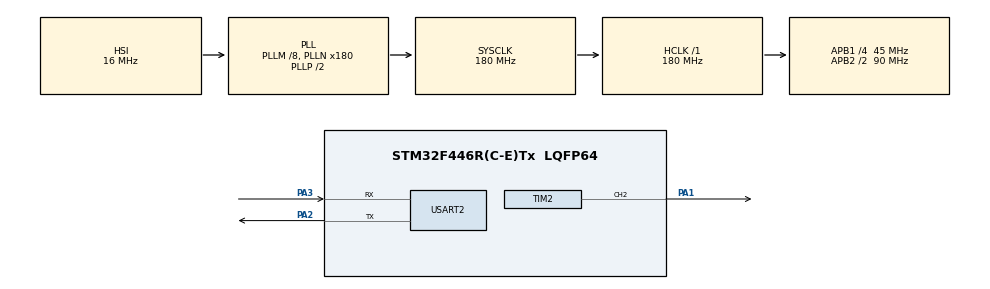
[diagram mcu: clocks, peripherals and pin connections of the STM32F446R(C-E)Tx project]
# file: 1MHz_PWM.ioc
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Mcu.Family=STM32F4
Mcu.Name=STM32F446R(C-E)Tx
Mcu.Package=LQFP64
NVIC.PriorityGroup=NVIC_PRIORITYGROUP_0
PA1.Signal=S_TIM2_CH2
PA13.Mode=Serial_Wire
PA13.Signal=SYS_JTMS-SWDIO
PA14.Mode=Serial_Wire
PA14.Signal=SYS_JTCK-SWCLK
PA2.Mode=Asynchronous
PA2.Signal=USART2_TX
PA3.Mode=Asynchronous
PA3.Signal=USART2_RX
PH0-OSC_IN.Mode=HSE-External-Oscillator
PH0-OSC_IN.Signal=RCC_OSC_IN
PH1-OSC_OUT.Mode=HSE-External-Oscillator
PH1-OSC_OUT.Signal=RCC_OSC_OUT
ProjectManager.HeapSize=0x200
ProjectManager.StackSize=0x400
ProjectManager.TargetToolchain=STM32CubeIDE
RCC.48MHZClocksFreq_Value=84000000
RCC.AHBFreq_Value=180000000
RCC.APB1CLKDivider=RCC_HCLK_DIV4
RCC.APB1Freq_Value=45000000
RCC.APB1TimFreq_Value=90000000
RCC.APB2CLKDivider=RCC_HCLK_DIV2
RCC.APB2Freq_Value=90000000
RCC.APB2TimFreq_Value=180000000
RCC.CortexFreq_Value=180000000
RCC.FLatency-AdvancedSettings=FLASH_LATENCY_5
RCC.HCLKFreq_Value=180000000
RCC.HSE_VALUE=8000000
RCC.HSI_VALUE=16000000
RCC.PLLM=8
RCC.PLLN=180
RCC.SYSCLKFreq_VALUE=180000000
RCC.SYSCLKSource=RCC_SYSCLKSOURCE_PLLCLK
RCC.USBFreq_Value=180000000
RCC.VCOOutputFreq_Value=360000000
SH.S_TIM2_CH2.0=TIM2_CH2,PWM Generation2 CH2
TIM2.Channel-PWM\ Generation2\ CH2=TIM_CHANNEL_2
TIM2.Period=179 
USART2.VirtualMode=VM_ASYNC
VP_TIM2_VS_ClockSourceINT.Mode=Internal
board=NUCLEO-F446RE

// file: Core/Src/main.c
/* USER CODE BEGIN Header */
/**
  ******************************************************************************
  * @file           : main.c
  * @brief          : Main program body
  ******************************************************************************
  * @attention
  *
  * Copyright (c) 2026 STMicroelectronics.
  * All rights reserved.
  *
  ******************************************************************************
  */
/* USER CODE END Header */

#include "main.h"
#include <stdlib.h>
//for an example

TIM_HandleTypeDef htim2;
UART_HandleTypeDef huart2;

/* USER CODE BEGIN PV */
uint8_t rx_char;
char rx_buffer[4];
uint32_t rx_index = 0;
uint8_t rx_overflow = 0;

char *endptr;
unsigned long requested_mhz;
/* USER CODE END PV */

void SystemClock_Config(void);
static void MX_GPIO_Init(void);
static void MX_TIM2_Init(void);
static void MX_USART2_UART_Init(void);

/* USER CODE BEGIN PFP */
void PWM_SetFrequency(uint32_t frequency_hz);
/* USER CODE END PFP */

int main(void)
{

  /* MCU Configuration--------------------------------------------------------*/

  HAL_Init();

  SystemClock_Config();

  MX_GPIO_Init();
  MX_TIM2_Init();
  MX_USART2_UART_Init();

  /* USER CODE BEGIN 2 */

  if (HAL_TIM_PWM_Start(&htim2, TIM_CHANNEL_2) != HAL_OK)
  {
    Error_Handler();
  }

  const char Values[] =
      "\r\nPWM controller ready\r\n"
      "Enter a frequency from 1 to 10 MHz, then press Enter.\r\n";

  HAL_UART_Transmit(&huart2, (uint8_t *)Values,
                    sizeof(Values) - 1U, HAL_MAX_DELAY);

  /* USER CODE END 2 */

  /* Infinite loop */
  while (1)
  {

    if (HAL_UART_Receive(&huart2, &rx_char, 1, HAL_MAX_DELAY) == HAL_OK)
    {
      if (rx_char == '\r')
      {
        /* Ignore carriage return */
      }
      else if (rx_char == '\n')
      {
        rx_buffer[rx_index] = '\0';

        if (rx_overflow == 0 && rx_index > 0U)
        {
          requested_mhz = strtoul(rx_buffer, &endptr, 10);

          if (endptr != rx_buffer &&
              *endptr == '\0' &&
              requested_mhz >= 1UL &&
              requested_mhz <= 10UL)
          {
            uint32_t requested_hz =
                (uint32_t)requested_mhz * 1000000U;

            PWM_SetFrequency(requested_hz);

            const char message[] = "PWM frequency updated\r\n";

            HAL_UART_Transmit(&huart2, (uint8_t *)message,sizeof(message) - 1U, HAL_MAX_DELAY);
          }
          else
          {
            const char message[] =
                "Invalid input. Enter 1 to 10 MHz.\r\n";

            HAL_UART_Transmit(&huart2, (uint8_t *)message,sizeof(message) - 1U, HAL_MAX_DELAY);
          }
        }
        else
        {
          const char message[] =
              "Invalid or empty input. Enter 1 to 10 MHz.\r\n";

          HAL_UART_Transmit(&huart2, (uint8_t *)message,sizeof(message) - 1U, HAL_MAX_DELAY);
        }

        rx_index = 0;
        rx_overflow = 0;
      }
      else
      {
        if (rx_index < sizeof(rx_buffer) - 1U)
        {
          rx_buffer[rx_index] = (char)rx_char;
          rx_index++;
        }
        else
        {
          rx_overflow = 1;
        }
      }
    }

  }
}

void SystemClock_Config(void)
{
  RCC_OscInitTypeDef RCC_OscInitStruct = {0};
  RCC_ClkInitTypeDef RCC_ClkInitStruct = {0};

  __HAL_RCC_PWR_CLK_ENABLE();
  __HAL_PWR_VOLTAGESCALING_CONFIG(PWR_REGULATOR_VOLTAGE_SCALE1);

  RCC_OscInitStruct.OscillatorType = RCC_OSCILLATORTYPE_HSI;
  RCC_OscInitStruct.HSIState = RCC_HSI_ON;
  RCC_OscInitStruct.HSICalibrationValue = RCC_HSICALIBRATION_DEFAULT;
  RCC_OscInitStruct.PLL.PLLState = RCC_PLL_ON;
  RCC_OscInitStruct.PLL.PLLSource = RCC_PLLSOURCE_HSI;
  RCC_OscInitStruct.PLL.PLLM = 8;
  RCC_OscInitStruct.PLL.PLLN = 180;
  RCC_OscInitStruct.PLL.PLLP = RCC_PLLP_DIV2;
  RCC_OscInitStruct.PLL.PLLQ = 2;
  RCC_OscInitStruct.PLL.PLLR = 2;

  if (HAL_RCC_OscConfig(&RCC_OscInitStruct) != HAL_OK)
  {
    Error_Handler();
  }

  /* Activate the Over-Drive mode */
  if (HAL_PWREx_EnableOverDrive() != HAL_OK)
  {
    Error_Handler();
  }

  RCC_ClkInitStruct.ClockType = RCC_CLOCKTYPE_HCLK |
                                RCC_CLOCKTYPE_SYSCLK |
                                RCC_CLOCKTYPE_PCLK1 |
                                RCC_CLOCKTYPE_PCLK2;

  RCC_ClkInitStruct.SYSCLKSource = RCC_SYSCLKSOURCE_PLLCLK;
  RCC_ClkInitStruct.AHBCLKDivider = RCC_SYSCLK_DIV1;
  RCC_ClkInitStruct.APB1CLKDivider = RCC_HCLK_DIV4;
  RCC_ClkInitStruct.APB2CLKDivider = RCC_HCLK_DIV2;

  if (HAL_RCC_ClockConfig(&RCC_ClkInitStruct, FLASH_LATENCY_5) != HAL_OK)
  {
    Error_Handler();
  }
}

static void MX_TIM2_Init(void)
{
  TIM_ClockConfigTypeDef sClockSourceConfig = {0};
  TIM_MasterConfigTypeDef sMasterConfig = {0};
  TIM_OC_InitTypeDef sConfigOC = {0};

  htim2.Instance = TIM2;
  htim2.Init.Prescaler = 0;
  htim2.Init.CounterMode = TIM_COUNTERMODE_UP;
  htim2.Init.Period = 89;
  htim2.Init.ClockDivision = TIM_CLOCKDIVISION_DIV1;
  htim2.Init.AutoReloadPreload = TIM_AUTORELOAD_PRELOAD_ENABLE;

  if (HAL_TIM_Base_Init(&htim2) != HAL_OK)
  {
    Error_Handler();
  }

  sClockSourceConfig.ClockSource = TIM_CLOCKSOURCE_INTERNAL;

  if (HAL_TIM_ConfigClockSource(&htim2, &sClockSourceConfig) != HAL_OK)
  {
    Error_Handler();
  }

  if (HAL_TIM_PWM_Init(&htim2) != HAL_OK)
  {
    Error_Handler();
  }

  sMasterConfig.MasterOutputTrigger = TIM_TRGO_RESET;
  sMasterConfig.MasterSlaveMode = TIM_MASTERSLAVEMODE_DISABLE;

  if (HAL_TIMEx_MasterConfigSynchronization(&htim2,
                                             &sMasterConfig) != HAL_OK)
  {
    Error_Handler();
  }

  sConfigOC.OCMode = TIM_OCMODE_PWM1;
  sConfigOC.Pulse = 45;
  sConfigOC.OCPolarity = TIM_OCPOLARITY_HIGH;
  sConfigOC.OCFastMode = TIM_OCFAST_DISABLE;

  if (HAL_TIM_PWM_ConfigChannel(&htim2, &sConfigOC,
                                TIM_CHANNEL_2) != HAL_OK)
  {
    Error_Handler();
  }

  HAL_TIM_MspPostInit(&htim2);
}

static void MX_USART2_UART_Init(void)
{
  huart2.Instance = USART2;
  huart2.Init.BaudRate = 115200;
  huart2.Init.WordLength = UART_WORDLENGTH_8B;
  huart2.Init.StopBits = UART_STOPBITS_1;
  huart2.Init.Parity = UART_PARITY_NONE;
  huart2.Init.Mode = UART_MODE_TX_RX;
  huart2.Init.HwFlowCtl = UART_HWCONTROL_NONE;
  huart2.Init.OverSampling = UART_OVERSAMPLING_16;

  if (HAL_UART_Init(&huart2) != HAL_OK)
  {
    Error_Handler();
  }
}

static void MX_GPIO_Init(void)
{

  __HAL_RCC_GPIOH_CLK_ENABLE();
  __HAL_RCC_GPIOA_CLK_ENABLE();

}

/* USER CODE BEGIN 4 */

void PWM_SetFrequency(uint32_t frequency_hz)
{
  if (frequency_hz < 1000000U || frequency_hz > 10000000U)
  {
    return;
  }

  uint32_t ticks = (90000000U + frequency_hz / 2U) / frequency_hz;
  uint32_t arr_value = ticks - 1U;
  uint32_t ccr_value = ticks / 2U;

  TIM2->CR1 |= TIM_CR1_ARPE;
  TIM2->CCMR1 |= TIM_CCMR1_OC2PE;

  TIM2->CR1 |= TIM_CR1_UDIS;

  __HAL_TIM_SET_AUTORELOAD(&htim2, arr_value);
  __HAL_TIM_SET_COMPARE(&htim2, TIM_CHANNEL_2, ccr_value);

  TIM2->CR1 &= ~TIM_CR1_UDIS;
}

/* USER CODE END 4 */

void Error_Handler(void)
{
  __disable_irq();
  while (1)
  {
  }
}

#ifdef USE_FULL_ASSERT
/**
  * @brief  Reports the name of the source file and the source line number
  * @param  file: pointer to the source file name
  * @param  line: assert_param error line number
  * @retval None
  */
void assert_failed(uint8_t *file, uint32_t line)
{
  /* USER CODE BEGIN 6 */
  /* User can add his own implementation to report the source file name
     and line number, ex: printf("Wrong parameters value\r\n"); */
  /* USER CODE END 6 */
}
#endif /* USE_FULL_ASSERT */
